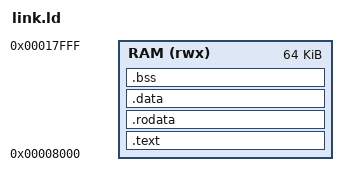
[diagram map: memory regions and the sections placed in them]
OUTPUT_ARCH(riscv)
ENTRY(_start)

MEMORY
{
    RAM (rwx) : ORIGIN = 0x8000, LENGTH = 64K
}

SECTIONS
{
    .text : { *(.text*) } > RAM
    .rodata : { *(.rodata*) } > RAM
    .data : { *(.data*) } > RAM
    .bss : { *(.bss*) } > RAM
}
